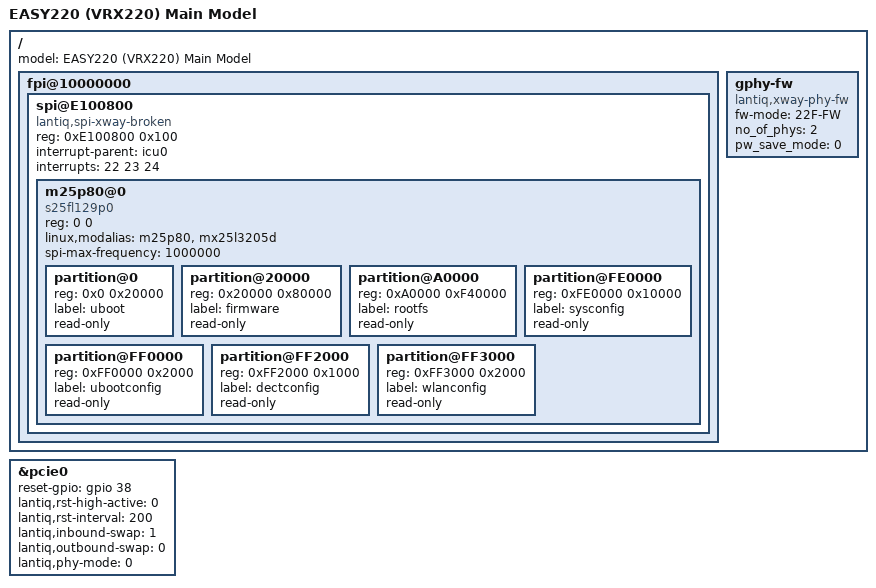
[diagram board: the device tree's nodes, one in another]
/dts-v1/;


/include/ "EASY220.dtsi"

/ {
	model = "EASY220 (VRX220) Main Model";

	fpi@10000000 {
		spi@E100800 {
			compatible = "lantiq,spi-xway-broken", "lantiq,spi-ssc";
			reg = <0xE100800 0x100>;
			interrupt-parent = <&icu0>;
			interrupts = <22 23 24>;
			#address-cells = <1>;
			#size-cells = <1>;

			m25p80@0 {
				#address-cells = <1>;
				#size-cells = <1>;
				compatible = "s25fl129p0";
				reg = <0 0>;
				linux,modalias = "m25p80", "mx25l3205d";
				spi-max-frequency = <1000000>;

				partition@0 {
					reg = <0x0 0x20000>;
					label = "uboot";
					read-only;
				};

				partition@20000 {
					reg = <0x20000 0x80000>;
					label = "firmware";
					read-only;
				};

				partition@A0000 {
					reg = <0xA0000 0xF40000>;
					label = "rootfs";
					read-only;
				};

				partition@FE0000 {
					reg = <0xFE0000 0x10000>;
					label = "sysconfig";
					read-only;
				};

				partition@FF0000 {
					reg = <0xFF0000 0x2000>;
					label = "ubootconfig";
					read-only;
				};
				
				partition@FF2000 {
					reg = <0xFF2000 0x1000>;
					label = "dectconfig";
					read-only;
				};
				
				partition@FF3000 {
					reg = <0xFF3000 0x2000>;
					label = "wlanconfig";
					read-only;
				};
			};
		};
	};
	gphy-fw {
		compatible = "lantiq,xway-phy-fw";
		fw-mode = "22F-FW"; /*"11G-FW"*/ /*22F-FW*/
		no_of_phys = <2>;
		pw_save_mode = <0>;
	};

};

&pcie0 {
	status = "ok";
	reset-gpio = <&gpio 38 0>;
	lantiq,rst-high-active = <0>; /* 0 - low activ, 1 -- high active */
	lantiq,rst-interval = <200>; /* in mili-seconds, up to 500 ms*/
	lantiq,inbound-swap = <1>; /* 0 -- no swap, 1 -- swap */
	lantiq,outbound-swap = <0>; /* 0 -- no swap, 1 -- swap */
	lantiq,phy-mode = <0>; /* 0 -36Mhz, 1 - 36MHzSSC, 2 - 25Mhz, 3 - 25MHzSSC, 4 - 100MHz */
};

